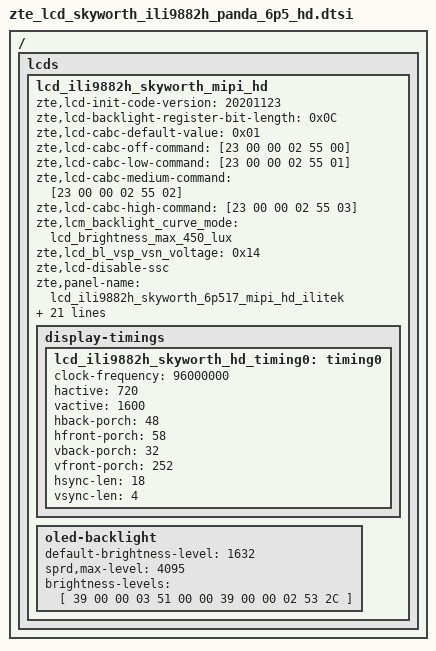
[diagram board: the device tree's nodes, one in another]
/ { lcds {
	lcd_ili9882h_skyworth_mipi_hd: lcd_ili9882h_skyworth_mipi_hd {
		zte,lcd-init-code-version = "20201123";
		zte,lcd-backlight-register-bit-length = <0x0C>;
		zte,lcd-cabc-default-value = <0x01>;
		zte,lcd-cabc-off-command = [23 00 00 02 55 00];
		zte,lcd-cabc-low-command = [23 00 00 02 55 01];
		zte,lcd-cabc-medium-command = [23 00 00 02 55 02];
		zte,lcd-cabc-high-command = [23 00 00 02 55 03];
		zte,lcm_backlight_curve_mode = "lcd_brightness_max_450_lux";
		zte,lcd_bl_vsp_vsn_voltage = <0x14>;
		zte,lcd-disable-ssc;
		zte,panel-name = "lcd_ili9882h_skyworth_6p517_mipi_hd_ilitek";
		zte,lcd-delay-open-bl-value = <30>;

		sprd,dsi-work-mode = <1>; /* video burst mode*/
		sprd,dsi-lane-number = <4>;
		sprd,dsi-color-format = "rgb888";

		sprd,phy-bit-clock = <700000>;	/* kbps */
		sprd,phy-escape-clock = <20000>;/* kHz */

		sprd,width-mm = <67932>;
		sprd,height-mm = <150960>;

		sprd,esd-check-enable = <0>;/* 0:close , 1:open */
		sprd,esd-check-mode = <0>;/* 0:REG ,1:TE  */
		sprd,esd-check-period = <1000>;
		sprd,esd-check-register = <0x0A>;
		sprd,esd-check-value = <0x9C>;

		sprd,reset-on-sequence = <1 5>, <0 10>, <1 35>;
		sprd,reset-off-sequence = <1 5>;
		sprd,initial-command = [
			39 00 00 04 FF 98 82 01
			39 00 00 02 00 42
			39 00 00 02 01 33
			39 00 00 02 02 01
			39 00 00 02 03 00
			39 00 00 02 04 02
			39 00 00 02 05 31
			39 00 00 02 07 00
			39 00 00 02 08 80
			39 00 00 02 09 81
			39 00 00 02 0a 71
			39 00 00 02 0b 00
			39 00 00 02 0c 01
			39 00 00 02 0d 01
			39 00 00 02 0e 00
			39 00 00 02 0f 00
			39 00 00 02 28 88
			39 00 00 02 29 88
			39 00 00 02 2a 00
			39 00 00 02 2b 00

			39 00 00 02 31 07
			39 00 00 02 32 0c
			39 00 00 02 33 22
			39 00 00 02 34 23
			39 00 00 02 35 07
			39 00 00 02 36 08
			39 00 00 02 37 16
			39 00 00 02 38 14
			39 00 00 02 39 12
			39 00 00 02 3a 10
			39 00 00 02 3b 21
			39 00 00 02 3c 07
			39 00 00 02 3d 07
			39 00 00 02 3e 07
			39 00 00 02 3f 07
			39 00 00 02 40 07
			39 00 00 02 41 07
			39 00 00 02 42 07
			39 00 00 02 43 07
			39 00 00 02 44 07
			39 00 00 02 45 07
			39 00 00 02 46 07

			39 00 00 02 47 07
			39 00 00 02 48 0d
			39 00 00 02 49 22
			39 00 00 02 4a 23
			39 00 00 02 4b 07
			39 00 00 02 4c 09
			39 00 00 02 4d 17
			39 00 00 02 4e 15
			39 00 00 02 4f 13
			39 00 00 02 50 11
			39 00 00 02 51 21
			39 00 00 02 52 07
			39 00 00 02 53 07
			39 00 00 02 54 07
			39 00 00 02 55 07
			39 00 00 02 56 07
			39 00 00 02 57 07
			39 00 00 02 58 07
			39 00 00 02 59 07
			39 00 00 02 5a 07
			39 00 00 02 5b 07
			39 00 00 02 5c 07

			39 00 00 02 61 07
			39 00 00 02 62 0d
			39 00 00 02 63 22
			39 00 00 02 64 23
			39 00 00 02 65 07
			39 00 00 02 66 09
			39 00 00 02 67 11
			39 00 00 02 68 13
			39 00 00 02 69 15
			39 00 00 02 6a 17
			39 00 00 02 6b 21
			39 00 00 02 6c 07
			39 00 00 02 6d 07
			39 00 00 02 6e 07
			39 00 00 02 6f 07
			39 00 00 02 70 07
			39 00 00 02 71 07
			39 00 00 02 72 07
			39 00 00 02 73 07
			39 00 00 02 74 07
			39 00 00 02 75 07
			39 00 00 02 76 07

			39 00 00 02 77 07
			39 00 00 02 78 0c
			39 00 00 02 79 22
			39 00 00 02 7a 23
			39 00 00 02 7b 07
			39 00 00 02 7c 08
			39 00 00 02 7d 10
			39 00 00 02 7e 12
			39 00 00 02 7f 14
			39 00 00 02 80 16
			39 00 00 02 81 21
			39 00 00 02 82 07
			39 00 00 02 83 07
			39 00 00 02 84 07
			39 00 00 02 85 07
			39 00 00 02 86 07
			39 00 00 02 87 07
			39 00 00 02 88 07
			39 00 00 02 89 07
			39 00 00 02 8a 07
			39 00 00 02 8b 07
			39 00 00 02 8c 07

			39 00 00 02 b0 33
			39 00 00 02 ba 06
			39 00 00 02 c0 07
			39 00 00 02 c1 00
			39 00 00 02 c2 00
			39 00 00 02 c3 00
			39 00 00 02 c4 00
			39 00 00 02 ca 44

			39 00 00 02 d0 01
			39 00 00 02 d1 22
			39 00 00 02 d3 40
			39 00 00 02 d5 51
			39 00 00 02 d6 20
			39 00 00 02 d7 01
			39 00 00 02 d8 00
			39 00 00 02 dc c2
			39 00 00 02 dd 10
			39 00 00 02 df b6

			39 00 00 02 e0 3E
			39 00 00 02 e2 47
			39 00 00 02 e7 54
			39 00 00 02 e6 22
			39 00 00 02 ee 15

			39 00 00 02 f1 00
			39 00 00 02 f2 00
			39 00 00 02 fa df


			39 00 00 04 FF 98 82 02
			39 00 00 02 F1 1C
			39 00 00 02 40 4B
			39 00 00 02 4B 5A
			39 00 00 02 50 CA

			39 00 00 02 51 50

			39 00 00 02 06 8D
			39 00 00 02 0B A0
			39 00 00 02 0C 80
			39 00 00 02 0D 1A
			39 00 00 02 0E 04
			39 00 00 02 4D CE

			39 00 00 02 73 04
			39 00 00 02 70 32


			39 00 00 04 FF 98 82 05
			39 00 00 02 A8 62
			39 00 00 02 03 00
			39 00 00 02 04 AF
			39 00 00 02 63 73
			39 00 00 02 64 73
			39 00 00 02 68 65
			39 00 00 02 69 6B
			39 00 00 02 6A A1
			39 00 00 02 6B 93
			39 00 00 02 00 01
			39 00 00 02 46 00
			39 00 00 02 45 01
			39 00 00 02 17 50
			39 00 00 02 18 01
			39 00 00 02 85 37
			39 00 00 02 86 0F


			39 00 00 04 FF 98 82 06
			39 00 00 02 D9 1F    /*10=3lane  1F=4Lane*/
			39 00 00 02 C0 40
			39 00 00 02 C1 16
			39 00 00 02 07 F7

			39 00 00 04 FF 98 82 08
			39 00 00 1C E0 40 24 97 D1 10 55 40 64 8D
						AD A9 DE 03 24 43 AA 63 8C A8
						CC FE EC 18 50 7D 03 EC
			39 00 00 1C E1 40 24 97 D1 10 55 40 64 8D
						AD A9 DE 03 24 43 AA 63 8C A8
						CC FE EC 18 50 7D 03 EC

			39 00 00 04 FF 98 82 0B
			39 00 00 02 9A 44
			39 00 00 02 9B 88
			39 00 00 02 9C 03
			39 00 00 02 9D 03
			39 00 00 02 9E 71
			39 00 00 02 9F 71
			39 00 00 02 AB E0

			39 00 00 04 FF 98 82 0E
			39 00 00 02 02 09
			39 00 00 02 11 50
			39 00 00 02 13 10
			39 00 00 02 00 A0

			39 00 00 04 FF 98 82 03
			39 00 00 02 83 20
			39 00 00 02 84 00

			39 00 00 04 FF 98 82 00
			39 00 00 02 35 00
			39 00 00 03 68 04 00
			39 00 00 03 51 00 00
			39 00 00 02 53 24
			39 00 00 02 55 01
			05 3C 00 01 11
			05 14 00 01 29
			];
		sprd,sleep-in-command = [
			13 0A 00 01 28
			13 78 00 01 10
			];
		sprd,sleep-out-command = [
			13 3C 00 01 11
			13 14 00 01 29
			];

		display-timings {
			lcd_ili9882h_skyworth_hd_timing0: timing0 {
			clock-frequency = <96000000>;
			hactive = <720>;
			vactive = <1600>;
			hback-porch = <48>;
			hfront-porch = <58>;
			vback-porch = <32>;
			vfront-porch = <252>;
			hsync-len = <18>;
			vsync-len = <4>;
			};
		};

		oled-backlight {
			default-brightness-level = <1632>;
			sprd,max-level = <4095>;
			brightness-levels = [
				39 00 00 03 51 00 00
				39 00 00 02 53 2C
			];
		};
	};
};};

